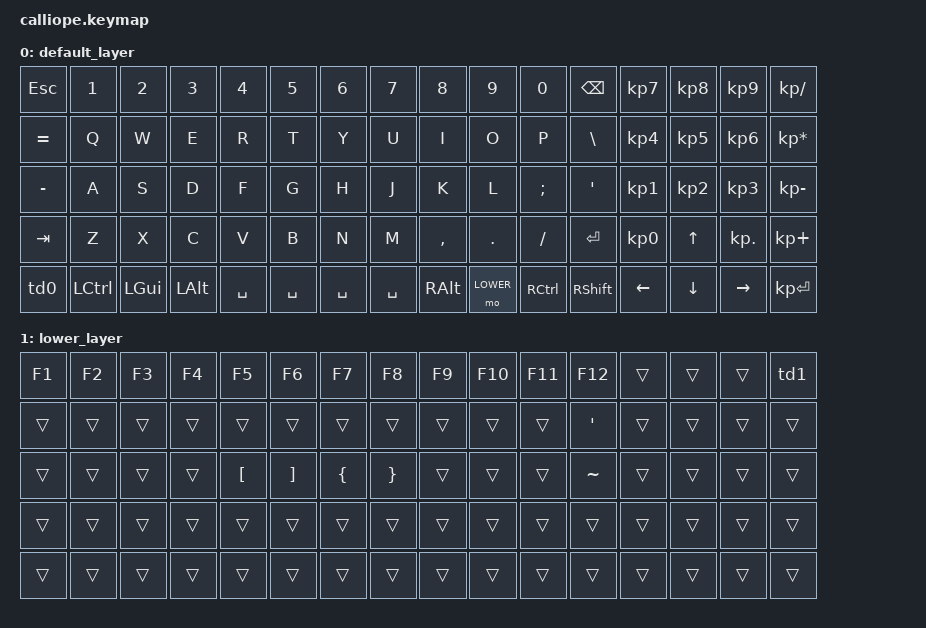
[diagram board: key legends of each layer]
/*
 * Copyright (c) 2020 The ZMK Contributors
 *
 * SPDX-License-Identifier: MIT
 */

#include <behaviors.dtsi>
#include <dt-bindings/zmk/keys.h>
#include <dt-bindings/zmk/bt.h>

#define TOP 0
#define LOWER 1

/ {
        behaviors {
        td0: capslock_0 {
            compatible = "zmk,behavior-tap-dance";
            #binding-cells = <0>;
            tapping-term-ms = <200>;
            bindings = <&kp LSHFT>, <&kp CAPS>;

        td1: numlock_1 {
            compatible = "zmk,behavior-tap-dance";
            #binding-cells = <1>;
            tapping-term-ms = <200>;
            bindings = <&kp KP_DIVIDE>, <&kp KP_NUM>;
                };
            };
        
        keymap {
                compatible = "zmk,keymap";

                default_layer {
//------------------------------------------------------------------------------------------
// |  ESC |  1  |  2  |  3  |  4  |  5  |   |  6  |  7   |  8  |  9  |  0  | BKSP |  7   |  8   |  9  |   /   |
// |   =  |  Q  |  W  |  E  |  R  |  T  |   |  Y  |  U   |  I  |  O  |  P  |  \   |  4   |  5   |  6  |   *   |
// |   -  |  A  |  S  |  D  |  F  |  G  |   |  H  |  J   |  K  |  L  |  ;  |  '   |  1   |  2   |  3  |   -   | 
// |  TAB |  Z  |  X  |  C  |  V  |  B  |   |  N  |  M   |  ,  |  .  |  /  | ENTR |  0   |  up  |  .  |   +   |
// | SHFT |L.CTL| Win | ALT | SPC | SPC |   | SPC |  SPC | ALT | FN  |R.CTL| SFT  | left | down |right| ENTR  |
// -----------------------------------------------------------------------------------------
                        bindings = <
   &kp ESC   &kp N1    &kp N2   &kp N3   &kp N4    &kp N5        &kp N6    &kp N7     &kp N8     &kp N9     &kp N0    &kp BSPC   &kp KP_N7  &kp KP_N8  &kp KP_N9  &kp KP_DIVIDE
   &kp EQUAL &kp Q     &kp W    &kp E    &kp R     &kp T         &kp Y     &kp U      &kp I      &kp O      &kp P     &kp BSLH   &kp KP_N4  &kp KP_N5  &kp KP_N6  &kp KP_MULTIPLY
   &kp MINUS &kp A     &kp S    &kp D    &kp F     &kp G         &kp H     &kp J      &kp K      &kp L      &kp SEMI  &kp SQT    &kp KP_N1  &kp KP_N2  &kp KP_N3  &kp KP_MINUS
   &kp TAB   &kp Z     &kp X    &kp C    &kp V     &kp B         &kp N     &kp M      &kp COMMA  &kp DOT    &kp FSLH  &kp ENTER  &kp KP_N0  &kp UP     &kp KP_DOT &kp KP_PLUS
   &td0      &kp LCTRL &kp LGUI &kp LALT &kp SPACE &kp SPACE     &kp SPACE &kp SPACE  &kp RALT   &mo LOWER  &kp RCTRL &kp RSHFT  &kp LEFT   &kp DOWN   &kp RIGHT  &kp KP_ENTER
                        >;
                };
                lower_layer {
//-----------------------------------------------------------------------------------------
// |  F1 |  F2  |  F3  |  F4  |  F5  |  F6  |   |  F7  |  F8   |  F9  |  F10  |  F11  | F12 |     |     |     |      |
// |     |      |      |      |      |      |   |      |       |      |       |       |  `  |     |     |     |      |
// |     |      |      |      |   [  |   ]  |   |   {  |   }   |      |       |       |  ~  |     |     |     |      | 
// |     |      |      |      |      |      |   |      |       |      |       |       |     |     |     |     |      |
// |     |      |      |      |      |      |   |      |       |      |       |       |     |     |     |     |      |
// -----------------------------------------------------------------------------------------
                        bindings = <
   &kp F1   &kp F2    &kp F3   &kp F4   &kp F5    &kp F6       &kp F7    &kp F8     &kp F9     &kp F10     &kp F11   &kp F12   &trans  &trans  &trans   &td1
   &trans   &trans    &trans   &trans   &trans    &trans       &trans    &trans     &trans     &trans      &trans    &kp APOS  &trans  &trans  &trans   &trans
   &trans   &trans    &trans   &trans   &kp LBKT  &kp RBKT     &kp LBRC  &kp RBRC   &trans     &trans      &trans    &kp TILDE &trans  &trans  &trans   &trans
   &trans   &trans    &trans   &trans   &trans    &trans       &trans    &trans     &trans     &trans      &trans    &trans    &trans  &trans  &trans   &trans
   &trans   &trans    &trans   &trans   &trans    &trans       &trans    &trans     &trans     &trans      &trans    &trans    &trans  &trans  &trans   &trans
                        >;
                };
        };
};
